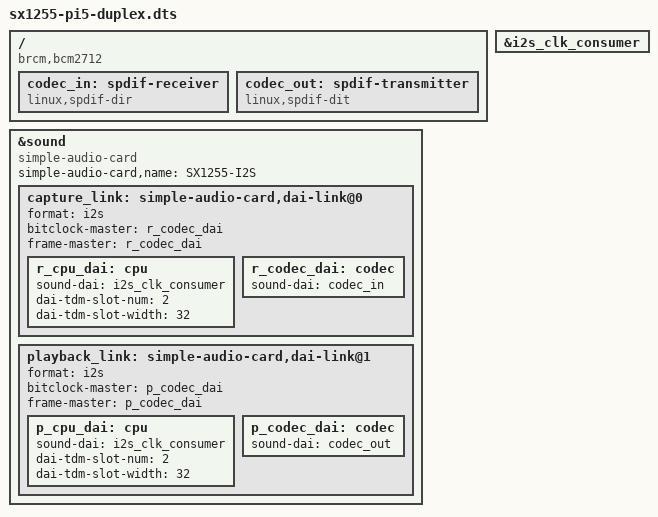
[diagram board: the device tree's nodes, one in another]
/dts-v1/;
/plugin/;

/ {
	compatible = "brcm,bcm2712";

	/*
	 * The SX1255 supplies BCLK and LRCLK. On BCM2712/RP1, i2s@a4000 is
	 * the clock-consumer instance; i2s@a0000 is the producer instance.
	 */
	fragment@0 {
		target = <&i2s_clk_consumer>;
		__overlay__ {
			#sound-dai-cells = <0>;
			status = "okay";
		};
	};

	fragment@1 {
		target-path = "/";
		__overlay__ {
			codec_in: spdif-receiver {
				#address-cells = <0>;
				#size-cells = <0>;
				#sound-dai-cells = <0>;
				compatible = "linux,spdif-dir";
				status = "okay";
			};

			codec_out: spdif-transmitter {
				#address-cells = <0>;
				#size-cells = <0>;
				#sound-dai-cells = <0>;
				compatible = "linux,spdif-dit";
				status = "okay";
			};
		};
	};

	fragment@2 {
		target = <&sound>;
		__overlay__ {
			compatible = "simple-audio-card";
			simple-audio-card,name = "SX1255-I2S";
			status = "okay";

			capture_link: simple-audio-card,dai-link@0 {
				format = "i2s";
				bitclock-master = <&r_codec_dai>;
				frame-master = <&r_codec_dai>;

				r_cpu_dai: cpu {
					sound-dai = <&i2s_clk_consumer>;
					dai-tdm-slot-num = <2>;
					dai-tdm-slot-width = <32>;
				};

				r_codec_dai: codec {
					sound-dai = <&codec_in>;
				};
			};

			playback_link: simple-audio-card,dai-link@1 {
				format = "i2s";
				bitclock-master = <&p_codec_dai>;
				frame-master = <&p_codec_dai>;

				p_cpu_dai: cpu {
					sound-dai = <&i2s_clk_consumer>;
					dai-tdm-slot-num = <2>;
					dai-tdm-slot-width = <32>;
				};

				p_codec_dai: codec {
					sound-dai = <&codec_out>;
				};
			};
		};
	};
};
